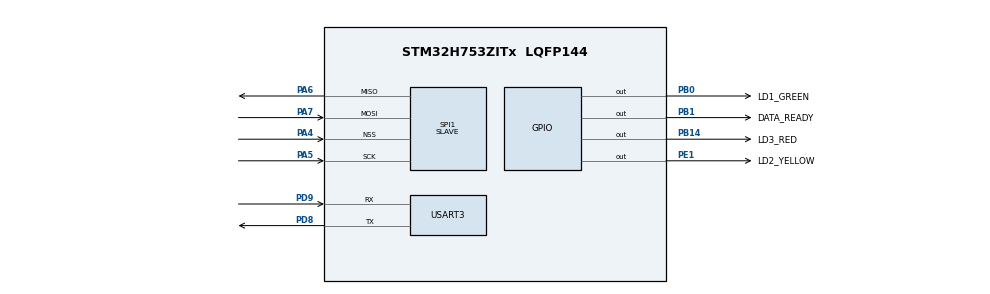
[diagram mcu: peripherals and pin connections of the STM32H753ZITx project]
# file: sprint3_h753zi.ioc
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CORTEX_M7.default_mode_Activation=1
FREERTOS.Tasks01=ledTask,8,128,StartLedTask,Default,NULL,Dynamic,NULL,NULL;telemetryTask,40,256,StartTelemetryTask,Default,NULL,Dynamic,NULL,NULL
FREERTOS.configUSE_NEWLIB_REENTRANT=1
Mcu.Family=STM32H7
Mcu.Name=STM32H753ZITx
Mcu.Package=LQFP144
NVIC.PriorityGroup=NVIC_PRIORITYGROUP_4
NVIC.SPI1_IRQn=true\:5\:0\:false\:false\:true\:true\:true\:true\:true
NVIC.TIM6_DAC_IRQn=true\:15\:0\:false\:false\:true\:false\:false\:true\:true
NVIC.TimeBase=TIM6_DAC_IRQn
NVIC.TimeBaseIP=TIM6
PA4.Mode=NSS_Signal_Hard_Input
PA4.Signal=SPI1_NSS
PA5.Mode=Full_Duplex_Slave
PA5.Signal=SPI1_SCK
PA6.Mode=Full_Duplex_Slave
PA6.Signal=SPI1_MISO
PA7.Mode=Full_Duplex_Slave
PA7.Signal=SPI1_MOSI
PB0.GPIO_Label=LD1_GREEN
PB0.Signal=GPIO_Output
PB1.GPIO_Label=DATA_READY
PB1.Signal=GPIO_Output
PB14.GPIO_Label=LD3_RED
PB14.Signal=GPIO_Output
PD8.Mode=Asynchronous
PD8.Signal=USART3_TX
PD9.Mode=Asynchronous
PD9.Signal=USART3_RX
PE1.GPIO_Label=LD2_YELLOW
PE1.Signal=GPIO_Output
ProjectManager.HeapSize=0x200
ProjectManager.StackSize=0x400
ProjectManager.TargetToolchain=STM32CubeIDE
RCC.ADCFreq_Value=129000000
RCC.APB1Freq_Value=32000000
RCC.APB2Freq_Value=64000000
RCC.APB3Freq_Value=64000000
RCC.APB4Freq_Value=64000000
RCC.CortexFreq_Value=64000000
RCC.D2PPRE1=RCC_APB1_DIV2
RCC.DIVM1=4
RCC.DIVN1=10
RCC.HCLKFreq_Value=64000000
RCC.PLLFRACN=0
RCC.SYSCLKFreq_VALUE=64000000
RCC.USBFreq_Value=80000000
SPI1.DataSize=SPI_DATASIZE_8BIT
SPI1.Direction=SPI_DIRECTION_2LINES
SPI1.Mode=SPI_MODE_SLAVE
SPI1.VirtualNSS=VM_NSSHARD
SPI1.VirtualType=VM_SLAVE
USART3.VirtualMode-Asynchronous=VM_ASYNC
VP_FREERTOS_VS_CMSIS_V2.Mode=CMSIS_V2
VP_MEMORYMAP_VS_MEMORYMAP.Mode=CurAppReg
VP_SYS_VS_tim6.Mode=TIM6
board=custom

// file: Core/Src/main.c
/* USER CODE BEGIN Header */
/**
  ******************************************************************************
  * @file           : main.c
  * @brief          : Main program body
  ******************************************************************************
  * @attention
  *
  * Copyright (c) 2026 STMicroelectronics.
  * All rights reserved.
  *
  * This software is licensed under terms that can be found in the LICENSE file
  * in the root directory of this software component.
  * If no LICENSE file comes with this software, it is provided AS-IS.
  *
  ******************************************************************************
  */
/* USER CODE END Header */
#include "main.h"
#include "cmsis_os.h"

/* USER CODE BEGIN Includes */
#include "ipc_bridge.h"

/* USER CODE END Includes */

SPI_HandleTypeDef hspi1;

UART_HandleTypeDef huart3;

/* Definitions for ledTask */
osThreadId_t ledTaskHandle;
const osThreadAttr_t ledTask_attributes = {
  .name = "ledTask",
  .stack_size = 128 * 4,
  .priority = (osPriority_t) osPriorityLow,
};
/* Definitions for telemetryTask */
osThreadId_t telemetryTaskHandle;
const osThreadAttr_t telemetryTask_attributes = {
  .name = "telemetryTask",
  .stack_size = 256 * 4,
  .priority = (osPriority_t) osPriorityHigh,
};

void SystemClock_Config(void);
static void MPU_Config(void);
static void MX_GPIO_Init(void);
static void MX_SPI1_Init(void);
static void MX_USART3_UART_Init(void);
void StartLedTask(void *argument);
void StartTelemetryTask(void *argument);

int main(void)
{

  /* MPU Configuration--------------------------------------------------------*/
  MPU_Config();

  /* MCU Configuration--------------------------------------------------------*/

  /* Reset of all peripherals, Initializes the Flash interface and the Systick. */
  HAL_Init();

  /* Configure the system clock */
  SystemClock_Config();

  /* Initialize all configured peripherals */
  MX_GPIO_Init();
  MX_SPI1_Init();
  MX_USART3_UART_Init();
  /* USER CODE BEGIN 2 */
  IPC_Bridge_Init();

  /* USER CODE END 2 */

  /* Init scheduler */
  osKernelInitialize();

  /* Create the thread(s) */
  /* creation of ledTask */
  ledTaskHandle = osThreadNew(StartLedTask, NULL, &ledTask_attributes);

  /* creation of telemetryTask */
  telemetryTaskHandle = osThreadNew(StartTelemetryTask, NULL, &telemetryTask_attributes);

  /* Start scheduler */
  osKernelStart();

  /* We should never get here as control is now taken by the scheduler */

  /* Infinite loop */
  while (1)
  {

  }
}

void SystemClock_Config(void)
{
  RCC_OscInitTypeDef RCC_OscInitStruct = {0};
  RCC_ClkInitTypeDef RCC_ClkInitStruct = {0};

  /** Supply configuration update enable
  */
  HAL_PWREx_ConfigSupply(PWR_LDO_SUPPLY);

  /** Configure the main internal regulator output voltage
  */
  __HAL_PWR_VOLTAGESCALING_CONFIG(PWR_REGULATOR_VOLTAGE_SCALE3);

  while(!__HAL_PWR_GET_FLAG(PWR_FLAG_VOSRDY)) {}

  /** Initializes the RCC Oscillators according to the specified parameters
  * in the RCC_OscInitTypeDef structure.
  */
  RCC_OscInitStruct.OscillatorType = RCC_OSCILLATORTYPE_HSI;
  RCC_OscInitStruct.HSIState = RCC_HSI_DIV1;
  RCC_OscInitStruct.HSICalibrationValue = RCC_HSICALIBRATION_DEFAULT;
  RCC_OscInitStruct.PLL.PLLState = RCC_PLL_ON;
  RCC_OscInitStruct.PLL.PLLSource = RCC_PLLSOURCE_HSI;
  RCC_OscInitStruct.PLL.PLLM = 4;
  RCC_OscInitStruct.PLL.PLLN = 10;
  RCC_OscInitStruct.PLL.PLLP = 2;
  RCC_OscInitStruct.PLL.PLLQ = 2;
  RCC_OscInitStruct.PLL.PLLR = 2;
  RCC_OscInitStruct.PLL.PLLRGE = RCC_PLL1VCIRANGE_3;
  RCC_OscInitStruct.PLL.PLLVCOSEL = RCC_PLL1VCOMEDIUM;
  RCC_OscInitStruct.PLL.PLLFRACN = 0;
  if (HAL_RCC_OscConfig(&RCC_OscInitStruct) != HAL_OK)
  {
    Error_Handler();
  }

  /** Initializes the CPU, AHB and APB buses clocks
  */
  RCC_ClkInitStruct.ClockType = RCC_CLOCKTYPE_HCLK|RCC_CLOCKTYPE_SYSCLK
                              |RCC_CLOCKTYPE_PCLK1|RCC_CLOCKTYPE_PCLK2
                              |RCC_CLOCKTYPE_D3PCLK1|RCC_CLOCKTYPE_D1PCLK1;
  RCC_ClkInitStruct.SYSCLKSource = RCC_SYSCLKSOURCE_HSI;
  RCC_ClkInitStruct.SYSCLKDivider = RCC_SYSCLK_DIV1;
  RCC_ClkInitStruct.AHBCLKDivider = RCC_HCLK_DIV1;
  RCC_ClkInitStruct.APB3CLKDivider = RCC_APB3_DIV1;
  RCC_ClkInitStruct.APB1CLKDivider = RCC_APB1_DIV2;
  RCC_ClkInitStruct.APB2CLKDivider = RCC_APB2_DIV1;
  RCC_ClkInitStruct.APB4CLKDivider = RCC_APB4_DIV1;

  if (HAL_RCC_ClockConfig(&RCC_ClkInitStruct, FLASH_LATENCY_1) != HAL_OK)
  {
    Error_Handler();
  }
}

static void MX_SPI1_Init(void)
{

  /* SPI1 parameter configuration*/
  hspi1.Instance = SPI1;
  hspi1.Init.Mode = SPI_MODE_SLAVE;
  hspi1.Init.Direction = SPI_DIRECTION_2LINES;
  hspi1.Init.DataSize = SPI_DATASIZE_8BIT;
  hspi1.Init.CLKPolarity = SPI_POLARITY_LOW;
  hspi1.Init.CLKPhase = SPI_PHASE_1EDGE;
  hspi1.Init.NSS = SPI_NSS_HARD_INPUT;
  hspi1.Init.FirstBit = SPI_FIRSTBIT_MSB;
  hspi1.Init.TIMode = SPI_TIMODE_DISABLE;
  hspi1.Init.CRCCalculation = SPI_CRCCALCULATION_DISABLE;
  hspi1.Init.CRCPolynomial = 0x0;
  hspi1.Init.NSSPMode = SPI_NSS_PULSE_DISABLE;
  hspi1.Init.NSSPolarity = SPI_NSS_POLARITY_LOW;
  hspi1.Init.FifoThreshold = SPI_FIFO_THRESHOLD_01DATA;
  hspi1.Init.TxCRCInitializationPattern = SPI_CRC_INITIALIZATION_ALL_ZERO_PATTERN;
  hspi1.Init.RxCRCInitializationPattern = SPI_CRC_INITIALIZATION_ALL_ZERO_PATTERN;
  hspi1.Init.MasterSSIdleness = SPI_MASTER_SS_IDLENESS_00CYCLE;
  hspi1.Init.MasterInterDataIdleness = SPI_MASTER_INTERDATA_IDLENESS_00CYCLE;
  hspi1.Init.MasterReceiverAutoSusp = SPI_MASTER_RX_AUTOSUSP_DISABLE;
  hspi1.Init.MasterKeepIOState = SPI_MASTER_KEEP_IO_STATE_DISABLE;
  hspi1.Init.IOSwap = SPI_IO_SWAP_DISABLE;
  if (HAL_SPI_Init(&hspi1) != HAL_OK)
  {
    Error_Handler();
  }

}

static void MX_USART3_UART_Init(void)
{

  huart3.Instance = USART3;
  huart3.Init.BaudRate = 115200;
  huart3.Init.WordLength = UART_WORDLENGTH_8B;
  huart3.Init.StopBits = UART_STOPBITS_1;
  huart3.Init.Parity = UART_PARITY_NONE;
  huart3.Init.Mode = UART_MODE_TX_RX;
  huart3.Init.HwFlowCtl = UART_HWCONTROL_NONE;
  huart3.Init.OverSampling = UART_OVERSAMPLING_16;
  huart3.Init.OneBitSampling = UART_ONE_BIT_SAMPLE_DISABLE;
  huart3.Init.ClockPrescaler = UART_PRESCALER_DIV1;
  huart3.AdvancedInit.AdvFeatureInit = UART_ADVFEATURE_NO_INIT;
  if (HAL_UART_Init(&huart3) != HAL_OK)
  {
    Error_Handler();
  }
  if (HAL_UARTEx_SetTxFifoThreshold(&huart3, UART_TXFIFO_THRESHOLD_1_8) != HAL_OK)
  {
    Error_Handler();
  }
  if (HAL_UARTEx_SetRxFifoThreshold(&huart3, UART_RXFIFO_THRESHOLD_1_8) != HAL_OK)
  {
    Error_Handler();
  }
  if (HAL_UARTEx_DisableFifoMode(&huart3) != HAL_OK)
  {
    Error_Handler();
  }

}

static void MX_GPIO_Init(void)
{
  GPIO_InitTypeDef GPIO_InitStruct = {0};

  /* GPIO Ports Clock Enable */
  __HAL_RCC_GPIOA_CLK_ENABLE();
  __HAL_RCC_GPIOB_CLK_ENABLE();
  __HAL_RCC_GPIOD_CLK_ENABLE();
  __HAL_RCC_GPIOE_CLK_ENABLE();

  /*Configure GPIO pin Output Level */
  HAL_GPIO_WritePin(GPIOB, LD1_GREEN_Pin|DATA_READY_Pin|LD3_RED_Pin, GPIO_PIN_RESET);

  /*Configure GPIO pin Output Level */
  HAL_GPIO_WritePin(LD2_YELLOW_GPIO_Port, LD2_YELLOW_Pin, GPIO_PIN_RESET);

  /*Configure GPIO pins : LD1_GREEN_Pin DATA_READY_Pin LD3_RED_Pin */
  GPIO_InitStruct.Pin = LD1_GREEN_Pin|DATA_READY_Pin|LD3_RED_Pin;
  GPIO_InitStruct.Mode = GPIO_MODE_OUTPUT_PP;
  GPIO_InitStruct.Pull = GPIO_NOPULL;
  GPIO_InitStruct.Speed = GPIO_SPEED_FREQ_LOW;
  HAL_GPIO_Init(GPIOB, &GPIO_InitStruct);

  /*Configure GPIO pin : LD2_YELLOW_Pin */
  GPIO_InitStruct.Pin = LD2_YELLOW_Pin;
  GPIO_InitStruct.Mode = GPIO_MODE_OUTPUT_PP;
  GPIO_InitStruct.Pull = GPIO_NOPULL;
  GPIO_InitStruct.Speed = GPIO_SPEED_FREQ_LOW;
  HAL_GPIO_Init(LD2_YELLOW_GPIO_Port, &GPIO_InitStruct);

}

void StartLedTask(void *argument)
{
  /* USER CODE BEGIN 5 */
  /* Infinite loop */
  for(;;)
  {
	  // Toggle Green OS Heartbeat every 500ms (1 Hz)
	  HAL_GPIO_TogglePin(LD1_GREEN_GPIO_Port, LD1_GREEN_Pin);
	  osDelay(500);
  }
  /* USER CODE END 5 */
}

void StartTelemetryTask(void *argument)
{
  /* USER CODE BEGIN StartTelemetryTask */
  /* Infinite loop */
  for(;;)
  {
      IPC_Bridge_Task();
	 // Visual TX indicator moved to the RED LED
	  HAL_GPIO_TogglePin(LD3_RED_GPIO_Port, LD3_RED_Pin);

	 // CRITICAL: This hands control back to the OS for 10ms,
	// allowing ledTask to run!
    osDelay(10);
  }
  /* USER CODE END StartTelemetryTask */
}

 /* MPU Configuration */

void MPU_Config(void)
{
  MPU_Region_InitTypeDef MPU_InitStruct = {0};

  /* Disables the MPU */
  HAL_MPU_Disable();

  /** Initializes and configures the Region and the memory to be protected
  */
  MPU_InitStruct.Enable = MPU_REGION_ENABLE;
  MPU_InitStruct.Number = MPU_REGION_NUMBER0;
  MPU_InitStruct.BaseAddress = 0x0;
  MPU_InitStruct.Size = MPU_REGION_SIZE_4GB;
  MPU_InitStruct.SubRegionDisable = 0x87;
  MPU_InitStruct.TypeExtField = MPU_TEX_LEVEL0;
  MPU_InitStruct.AccessPermission = MPU_REGION_NO_ACCESS;
  MPU_InitStruct.DisableExec = MPU_INSTRUCTION_ACCESS_DISABLE;
  MPU_InitStruct.IsShareable = MPU_ACCESS_SHAREABLE;
  MPU_InitStruct.IsCacheable = MPU_ACCESS_NOT_CACHEABLE;
  MPU_InitStruct.IsBufferable = MPU_ACCESS_NOT_BUFFERABLE;

  HAL_MPU_ConfigRegion(&MPU_InitStruct);
  /* Enables the MPU */
  HAL_MPU_Enable(MPU_PRIVILEGED_DEFAULT);

}

void HAL_TIM_PeriodElapsedCallback(TIM_HandleTypeDef *htim)
{
  if (htim->Instance == TIM6)
  {
    HAL_IncTick();
  }
}

void Error_Handler(void)
{
  __disable_irq();
  while (1)
  {
  }
}
